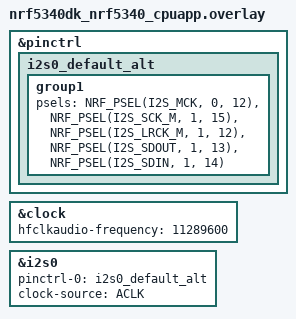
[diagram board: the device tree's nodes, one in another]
&pinctrl {
	i2s0_default_alt: i2s0_default_alt {
		group1 {
			psels = <NRF_PSEL(I2S_MCK, 0, 12)>,
				<NRF_PSEL(I2S_SCK_M, 1, 15)>,
				<NRF_PSEL(I2S_LRCK_M, 1, 12)>,
				<NRF_PSEL(I2S_SDOUT, 1, 13)>,
				<NRF_PSEL(I2S_SDIN, 1, 14)>;
		};
	};
};

&clock {
	hfclkaudio-frequency = <11289600>;
};

i2s_rxtx: &i2s0 {
	status = "okay";
	pinctrl-0 = <&i2s0_default_alt>;
	pinctrl-names = "default";
	clock-source = "ACLK";
};

#include "../app.overlay"
